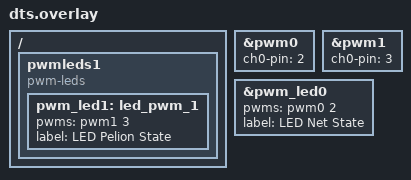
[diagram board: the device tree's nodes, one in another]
/ {
	pwmleds1 {
		compatible = "pwm-leds";
		status = "okay";

		pwm_led1: led_pwm_1 {
			status = "okay";
			pwms = <&pwm1 3>;
			label = "LED Pelion State";
		};
	};
};

&pwm0 {
	status = "okay";
	ch0-pin = <2>;
};

&pwm1 {
	status = "okay";
	ch0-pin = <3>;
};

&pwm_led0 {
	status = "okay";
	pwms = <&pwm0 2>;
	label = "LED Net State";
};
